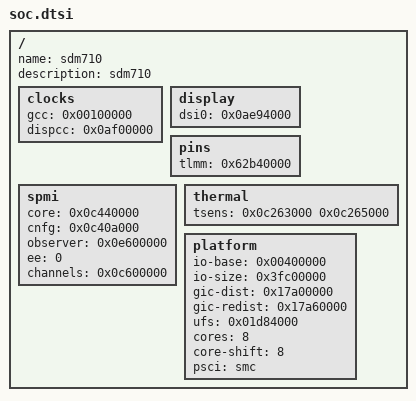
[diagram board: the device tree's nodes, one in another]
/dts-v1/;

// sdm710. Started by tools/boards.py new from phone.dts.
// What every board with this SoC shares: where its blocks are (Documentation/porting.md).
/ {
	name = "sdm710";
	description = "sdm710";

	// The clocks the display block's registers need before they can be read: for a "dcs" backlight and
	// the feature "display-scan". The addresses are in the tree; the offsets are not -- they are in Linux's
	// clock drivers for the SoC (gcc-CODENAME.c, dispcc-CODENAME.c).
	clocks {
		gcc = <0x00100000>;             // clock-controller@100000 (qcom,CODENAME-gcc); the only key of this section
		                                // that the part drivers need
		// gcc-disp-ahb-cbcr = <0x...>; // TO FILL IN: gcc_disp_ahb_clk: its .halt_reg
		dispcc = <0x0af00000>;          // clock-controller@af00000 (qcom,CODENAME-dispcc)
		// dispcc-mdss-gdscr = <0x...>; // TO FILL IN: the display block's power switch (mdss_core_gdsc): its .gdscr
		// dispcc-mdss-ahb-cbcr = <0x...>; // TO FILL IN: disp_cc_mdss_ahb_clk
	};

	display {
		dsi0 = <0x0ae94000>;            // the first DSI controller (cell-index 0), reg "dsi_ctrl"
	};

	// The SoC's own pins (TLMM), for the part drivers that drive them: the touch controllers', the speaker
	// amplifier's, the haptic motor's, the cameras'.
	pins {
		tlmm = <0x62b40000>;            // where GPIO 0's registers are; GPIO n's are 0x1000 n further. The pin
		                                // controller's node (qcom,CODENAME-pinctrl): in Linux's trees its reg; in
		                                // the vendor's, whose reg is the whole 16 MiB block, 0x100000 above it
	};

	// The PMIC arbiter (qcom,spmi-pmic-arb), by its reg-names: for the features "buttons-pmic",
	// "torch-pm8350c" and "camera-sm7325".
	spmi {
		core = <0x0c440000>;            // "core"
		cnfg = <0x0c40a000>;            // "cnfg"
		observer = <0x0e600000>;        // "obsrvr": reads
		ee = <0>;                       // qcom,ee; optional, 0 if left out
		channels = <0x0c600000>;        // "chnls": writes; optional, needed only by the drivers that write to a PMIC
	};

	// Temperature, for a board's thermal { }.
	thermal {
		tsens = <0x0c263000 0x0c265000>; // the TSENS controllers (at most eight), reg "tsens_tm_physical"
	};

	// The low-power audio subsystem's blocks on the microphones' path, for the feature "mic-wcd938x". From the
	// SoC's -audio.dtsi (the vendor's). tools/boards.py new finds the addresses and leaves the section commented
	// out, with the SoundWire pins to fill in.
	// lpass {
		// tx-macro = <0x...>;          // TO FILL IN: tx-macro@3220000 (qcom,tx-macro): the codec macro of the capture side
		// va-macro = <0x...>;          // TO FILL IN: va-macro@3370000 (qcom,va-macro)
		// tx-swr = <0x...>;            // TO FILL IN: the SoundWire master under the TX macro (qcom,swr-mstr): its reg
		// tx-swr-hctl = <0x...>;       // TO FILL IN: ... and its hardware control register, its qcom,swrm-hctl-reg
		// lpi = <0x62b40000>;          // the subsystem's own pins: lpi_pinctrl@33c0000 (qcom,lpi-pinctrl)
		// lpi-slew = <0x...>;          // TO FILL IN: ... and that node's qcom,slew-reg
		// swr-tx-pins = <0x...>;       // TO FILL IN: the TX SoundWire master's pins among them, its clock first, then its data
		// swr-tx-slew = <0x...>;       // TO FILL IN: each pin's field in that slew register (the vendor's pinctrl-lpi.c)
	// };

	// What the loader (arch/arm64/boot/) tells the kernel of the machine, for boards with a loader { } section.
	platform {
		io-base = <0x00400000>;         // one window over the SoC's peripherals, never 0 (7-series value)
		io-size = <0x3fc00000>;         // (these two are what the Snapdragon 7-series ports use)
		gic-dist = <0x17a00000>;        // the arm,gic-v3 node's reg: its first entry
		gic-redist = <0x17a60000>;      // ... its second
		ufs = <0x01d84000>;             // optional: the UFS host controller (the ufshc node's reg "ufs_mem"), for the
		                                // loader's and the kernel's own requests to the storage (ufs_native=)
		cores = <8>;                    // the cpu@ nodes
		core-shift = <8>;               // where the core's number is in its reg: 8 for 0x000, 0x100 ..., 0 for 0, 1 ...
		psci = "smc";                   // the psci node's method in the live FDT ([73 6d 63 00] = "smc")
	};
};
